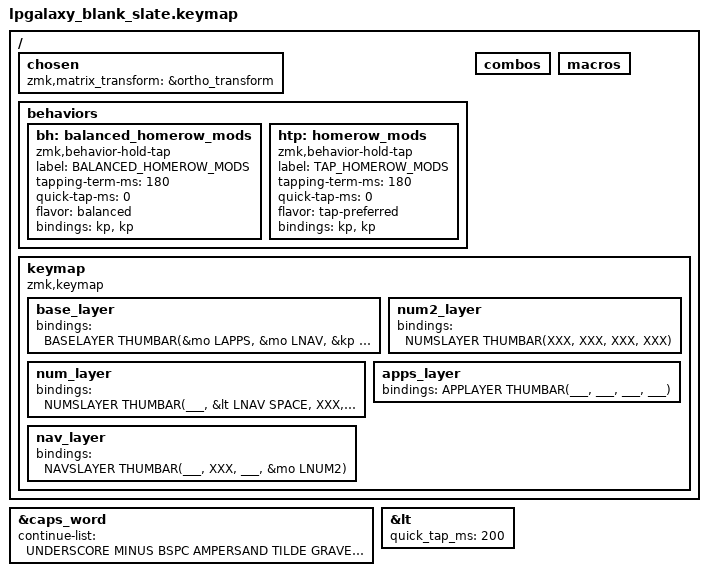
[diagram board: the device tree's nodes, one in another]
#define CENTERED


#include <behaviors.dtsi>
#include <dt-bindings/zmk/keys.h>
#include <dt-bindings/zmk/bt.h>
#include <dt-bindings/zmk/outputs.h>

#ifdef CENTERED
    #include "astonishing_layout.h"
#else
    #include "astonishing_left.h"
#endif


&caps_word {
    continue-list = <UNDERSCORE MINUS BSPC AMPERSAND TILDE GRAVE APOSTROPHE CARET>;
};

// Using layer taps on thumbs, having quick tap as well helps w/ repeating space/backspace
&lt { quick_tap_ms = <200>; };

 
/ {
    chosen {
       zmk,matrix_transform =
                       &ortho_transform;
    };

    behaviors {
        bh: balanced_homerow_mods {
            compatible = "zmk,behavior-hold-tap";
            label = "BALANCED_HOMEROW_MODS";
            #binding-cells = <2>;
            tapping-term-ms = <180>;    // <---[[moderate duration]]
            quick-tap-ms = <0>;
            flavor = "balanced";
            bindings = <&kp>, <&kp>;
        };
        htp: homerow_mods {
            compatible = "zmk,behavior-hold-tap";
            label = "TAP_HOMEROW_MODS";
            #binding-cells = <2>;
            tapping-term-ms = <180>;
            quick-tap-ms = <0>;
            flavor = "tap-preferred";
            bindings = <&kp>, <&kp>;
        };


    };

    combos {

        #ifdef CENTERED
            #include "combos.dtsi"
        #else
            #include "combos-left.dtsi"
        #endif
    };

    macros {
        #include "macros.dtsi"
    };

    // tap_dances {
    // 	shifty: shift_caps_word {
	// 	compatible = "zmk,behavior-tap-dance";
	// 	label = "TD_SHIFTY";
	// 	#binding-cells = <0>;
	// 	tapping-term-ms = <150>;
	// 	bindings = <&kp LSHFT>, <&caps_word>;
	// };
    // };

    keymap {
        compatible = "zmk,keymap";

        base_layer {
        bindings = <
            BASELAYER
            THUMBAR(&mo LAPPS, &mo LNAV, &kp SPACE, &mo LNUM)
        >;
        };

        num_layer {
        bindings = <
            NUMSLAYER
            THUMBAR(___, &lt LNAV SPACE, XXX, XXX)

        >;
        };

        nav_layer {
        bindings = <
            NAVSLAYER
            THUMBAR(___, XXX, ___, &mo LNUM2)
        >;
        };
        
        num2_layer {
        bindings = <
            NUMSLAYER
            THUMBAR(XXX, XXX, XXX, XXX)
        >;
        };
        
        apps_layer {
        bindings = <
            APPLAYER
            THUMBAR(___, ___, ___, ___)
        >;
        };

    };
};

